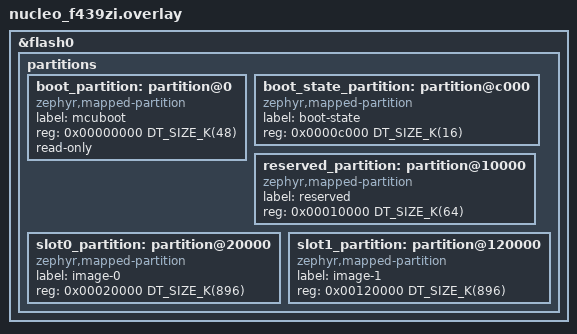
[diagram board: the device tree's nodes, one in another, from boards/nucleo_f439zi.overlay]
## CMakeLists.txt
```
# SPDX-License-Identifier: Apache-2.0
cmake_minimum_required(VERSION 3.28.0)

find_package(Zephyr REQUIRED HINTS $ENV{ZEPHYR_BASE})
project(sber_ota LANGUAGES C)

target_sources(app PRIVATE src/main.c src/rww_test.c)
```

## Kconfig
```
# Kconfig приложения: Zephyr подхватывает файл Kconfig в корне приложения
# автоматически; в конце обязательно source "Kconfig.zephyr".

mainmenu "sber-ota"

menu "sber-ota"

config SBER_OTA_AUTO_CONFIRM
	bool "Confirm running image after first answered network request"
	default y
	depends on MCUBOOT_IMG_MANAGER
	help
	  После обновления MCUboot запускает новый образ в состоянии "testing":
	  если до следующего сброса его не подтвердить, загрузчик откатит
	  предыдущий. Приложение подтверждает себя (boot_write_img_confirmed)
	  только после того, как приняло и ответило на первый UDP-запрос по сети:
	  это доказывает, что стек, драйвер Ethernet и обработчик живы.
	  Выключить, чтобы собрать "плохой" образ для демонстрации отката.

endmenu

source "Kconfig.zephyr"
```

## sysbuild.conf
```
# sysbuild: собрать MCUboot + приложение одной командой
#   west build -b nucleo_f439zi --sysbuild app/sber-ota -d build_sber_sb
SB_CONFIG_BOOTLOADER_MCUBOOT=y

# swap-move: не нужен scratch, образ в slot0 после обновления остаётся на своём
# адресе (приложение линкуется один раз). Запасной режим перед direct-XIP.
# Слоты 7+7 секторов по 128 КБ: swap-move требует num_pri == num_sec или
# num_pri == num_sec+1; при равенстве последний сектор primary уходит под
# сдвиг + trailer, полезный объём образа = 6 * 128 КБ - trailer.
SB_CONFIG_MCUBOOT_MODE_SWAP_USING_MOVE=y

# ECDSA P-256: подпись 64 байта, верификация быстрее RSA-2048 и меньше кода
# в загрузчике. Ключ по умолчанию — ТЕСТОВЫЙ root-ec-p256.pem из репозитория
# MCUboot (публично известен!). Боевой ключ задавать через
# SB_CONFIG_BOOT_SIGNATURE_KEY_FILE вне репозитория.
SB_CONFIG_BOOT_SIGNATURE_TYPE_ECDSA_P256=y
```

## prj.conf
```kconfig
# --- Сеть: только IPv4, UDP + TCP, BSD-сокеты ---
CONFIG_NETWORKING=y
CONFIG_NET_IPV4=y
CONFIG_NET_IPV6=n
CONFIG_NET_UDP=y
CONFIG_NET_TCP=y
CONFIG_NET_SOCKETS=y
CONFIG_POSIX_API=y
CONFIG_NET_CONNECTION_MANAGER=y

# Статический адрес платы (DHCP — шаг 4)
CONFIG_NET_CONFIG_SETTINGS=y
CONFIG_NET_CONFIG_NEED_IPV4=y
CONFIG_NET_CONFIG_MY_IPV4_ADDR="192.168.7.1"
CONFIG_NET_CONFIG_MY_IPV4_NETMASK="255.255.255.0"

# Буферы: эхо-сервер + будущая загрузка образа кусками 1–2 КБ
CONFIG_NET_PKT_RX_COUNT=16
CONFIG_NET_PKT_TX_COUNT=16
CONFIG_NET_BUF_RX_COUNT=64
CONFIG_NET_BUF_TX_COUNT=64
CONFIG_NET_MAX_CONTEXTS=10

# --- Ядро ---
CONFIG_MAIN_STACK_SIZE=4096
CONFIG_ENTROPY_GENERATOR=y
CONFIG_INIT_STACKS=y
CONFIG_REBOOT=y   # kernel reboot в shell; нужен и mcumgr os reset

# --- Flash: нужна для шага 2 (запись во второй банк) и проверки partitions ---
CONFIG_FLASH=y
CONFIG_FLASH_MAP=y
CONFIG_FLASH_PAGE_LAYOUT=y

# --- GPIO (LED «жив») ---
CONFIG_GPIO=y

# --- Логирование и shell (консоль ST-Link, 115200) ---
CONFIG_LOG=y
CONFIG_LOG_MODE_DEFERRED=y
CONFIG_PRINTK=y
CONFIG_NET_LOG=y
CONFIG_NET_STATISTICS=y
CONFIG_SHELL=y
CONFIG_NET_SHELL=y
CONFIG_FLASH_SHELL=y

# --- mcumgr / SMP по UDP (порт 1337): обновление и управление по сети ---
# Транспорт сам открывает сокет по NET_EVENT_L4_CONNECTED (UDP_AUTOMATIC_INIT).
CONFIG_MCUMGR=y
CONFIG_ZCBOR=y
CONFIG_CRC=y
CONFIG_NET_BUF=y
CONFIG_MCUMGR_TRANSPORT_UDP=y
CONFIG_MCUMGR_TRANSPORT_UDP_IPV4=y
CONFIG_MCUMGR_TRANSPORT_UDP_IPV6=n
# img_mgmt: приём образа в slot1 через stream_flash.
# ERASE_PROGRESSIVELY: стирать сектор по мере заполнения (1,9 с на 128 КБ),
# а не весь слот при первом куске (13,5 с > таймаут клиента).
CONFIG_IMG_MANAGER=y
CONFIG_STREAM_FLASH=y
CONFIG_IMG_ERASE_PROGRESSIVELY=y
CONFIG_MCUMGR_GRP_IMG=y
# os_mgmt: echo, reset, сведения о загрузчике
CONFIG_MCUMGR_GRP_OS=y
CONFIG_MCUMGR_GRP_OS_BOOTLOADER_INFO=y
# mcumgr params: клиент узнаёт размер буфера SMP и подбирает размер куска
CONFIG_MCUMGR_GRP_OS_MCUMGR_PARAMS=y
# Обработчики SMP работают в system workqueue — ему нужен стек побольше
CONFIG_SYSTEM_WORKQUEUE_STACK_SIZE=2304
```

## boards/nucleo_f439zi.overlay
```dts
/*
 * Раскладка flash STM32F439ZI (2 МБ, dual-bank) под MCUboot direct-XIP.
 *
 * Почему свой overlay: дефолтный nucleo_f439zi.dts даёт 32 КБ под bootloader
 * (не кратно секторной структуре 16/16/16/16/64 КБ) и несимметричные слоты
 * (896 КБ vs 768 КБ). Для direct-XIP слоты должны быть одинаковыми и лежать
 * на одинаковых смещениях внутри банков, чтобы совпадала структура секторов.
 *
 * Bank 1:  сектора 0-2   (3 x 16 КБ)  bootloader
 *          сектор  3     (16 КБ)      boot state / конфиг
 *          сектор  4     (64 КБ)      резерв
 *          сектора 5-11  (896 КБ)     slot0 (A) @ 0x08020000
 * Bank 2:  сектора 12-16              зеркало 0-4, не используются
 *          сектора 17-23 (896 КБ)     slot1 (B) @ 0x08120000
 */

/delete-node/ &boot_partition;
/delete-node/ &slot0_partition;
/delete-node/ &slot1_partition;

&flash0 {
	partitions {
		#address-cells = <1>;
		#size-cells = <1>;
		ranges;

		boot_partition: partition@0 {
			compatible = "zephyr,mapped-partition";
			label = "mcuboot";
			reg = <0x00000000 DT_SIZE_K(48)>;
			read-only;
		};

		boot_state_partition: partition@c000 {
			compatible = "zephyr,mapped-partition";
			label = "boot-state";
			reg = <0x0000c000 DT_SIZE_K(16)>;
		};

		reserved_partition: partition@10000 {
			compatible = "zephyr,mapped-partition";
			label = "reserved";
			reg = <0x00010000 DT_SIZE_K(64)>;
		};

		slot0_partition: partition@20000 {
			compatible = "zephyr,mapped-partition";
			label = "image-0";
			reg = <0x00020000 DT_SIZE_K(896)>;
		};

		slot1_partition: partition@120000 {
			compatible = "zephyr,mapped-partition";
			label = "image-1";
			reg = <0x00120000 DT_SIZE_K(896)>;
		};
	};
};
```

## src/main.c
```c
/*
 * sber-ota: UDP/TCP echo-сервер на NUCLEO-F439ZI (Zephyr).
 * Шаг 1: каркас приложения с сетью и логированием.
 * Шаг 2 (следующий): запись во второй банк flash при живой сети.
 *
 * SPDX-License-Identifier: Apache-2.0
 */

#include <zephyr/kernel.h>
#include <zephyr/logging/log.h>
#include <zephyr/drivers/gpio.h>
#include <zephyr/net/socket.h>
#include <zephyr/net/net_if.h>
#include <zephyr/net/net_mgmt.h>
#include <zephyr/net/net_event.h>
#include <zephyr/net/conn_mgr_monitor.h>
#include <zephyr/storage/flash_map.h>
#include <zephyr/dfu/mcuboot.h>
#include <errno.h>
#include <zephyr/app_version.h>
#include <cmsis_core.h>

/* Строки лога — ASCII: консоли/CI/парсеры не всегда понимают UTF-8 */
LOG_MODULE_REGISTER(sber_ota, LOG_LEVEL_INF);

#define ECHO_PORT      4242
#define RX_BUF_SIZE    1500
#define THREAD_STACK   2048
#define THREAD_PRIO    K_PRIO_PREEMPT(8)

static const struct gpio_dt_spec led = GPIO_DT_SPEC_GET(DT_ALIAS(led0), gpios);

/* Серверы стартуют после события L4_CONNECTED от connection manager */
static K_SEM_DEFINE(net_ready, 0, 1);

static void l4_event_handler(uint64_t event, struct net_if *iface, void *info,
			     size_t info_length, void *user_data)
{
	ARG_UNUSED(iface);
	ARG_UNUSED(info);
	ARG_UNUSED(info_length);
	ARG_UNUSED(user_data);

	if (event == NET_EVENT_L4_CONNECTED) {
		LOG_INF("network up");
		k_sem_give(&net_ready);
	} else if (event == NET_EVENT_L4_DISCONNECTED) {
		LOG_WRN("network down");
	}
}

NET_MGMT_REGISTER_EVENT_HANDLER(l4_handler,
				NET_EVENT_L4_CONNECTED | NET_EVENT_L4_DISCONNECTED,
				l4_event_handler, NULL);

/*
 * Подтверждение образа после обновления. MCUboot запускает новый образ как
 * "testing"; без подтверждения следующий сброс откатит предыдущий. Критерий
 * "образ исправен" здесь — принят и отвечен первый UDP-запрос: значит, стек,
 * драйвер Ethernet и приложение живы и доступны для скрипта обновления.
 */
static void confirm_image_after_first_reply(void)
{
	static bool done;
	int rc;

	if (done) {
		return;
	}
	done = true;

	if (!IS_ENABLED(CONFIG_SBER_OTA_AUTO_CONFIRM)) {
		LOG_WRN("auto-confirm disabled: image stays in testing state");
		return;
	}
	if (boot_is_img_confirmed()) {
		return;
	}
	rc = boot_write_img_confirmed();
	if (rc) {
		LOG_ERR("boot_write_img_confirmed: %d", rc);
	} else {
		LOG_INF("image confirmed after first network reply");
	}
}

static void wait_net_ready(void)
{
	k_sem_take(&net_ready, K_FOREVER);
	k_sem_give(&net_ready); /* передать эстафету второму потоку */
}

/* ---------- UDP echo ---------- */
static void udp_echo_thread(void *a, void *b, void *c)
{
	static uint8_t buf[RX_BUF_SIZE];
	struct sockaddr_in addr = {
		.sin_family = AF_INET,
		.sin_port = htons(ECHO_PORT),
		.sin_addr.s_addr = htonl(INADDR_ANY),
	};
	int sock;

	wait_net_ready();

	sock = zsock_socket(AF_INET, SOCK_DGRAM, IPPROTO_UDP);
	if (sock < 0) {
		LOG_ERR("UDP socket: %d", errno);
		return;
	}
	if (zsock_bind(sock, (struct sockaddr *)&addr, sizeof(addr)) < 0) {
		LOG_ERR("UDP bind: %d", errno);
		zsock_close(sock);
		return;
	}
	LOG_INF("UDP echo listening on port %d", ECHO_PORT);

	while (1) {
		struct sockaddr_in peer;
		socklen_t peer_len = sizeof(peer);
		ssize_t n = zsock_recvfrom(sock, buf, sizeof(buf), 0,
					   (struct sockaddr *)&peer, &peer_len);

		if (n < 0) {
			LOG_ERR("UDP recvfrom: %d", errno);
			continue;
		}
		if (zsock_sendto(sock, buf, n, 0, (struct sockaddr *)&peer, peer_len) < 0) {
			LOG_ERR("UDP sendto: %d", errno);
			continue;
		}
		confirm_image_after_first_reply();
	}
}

/* ---------- TCP echo (один клиент за раз) ---------- */
static void tcp_echo_thread(void *a, void *b, void *c)
{
	static uint8_t buf[RX_BUF_SIZE];
	struct sockaddr_in addr = {
		.sin_family = AF_INET,
		.sin_port = htons(ECHO_PORT),
		.sin_addr.s_addr = htonl(INADDR_ANY),
	};
	int sock;

	wait_net_ready();

	sock = zsock_socket(AF_INET, SOCK_STREAM, IPPROTO_TCP);
	if (sock < 0) {
		LOG_ERR("TCP socket: %d", errno);
		return;
	}
	if (zsock_bind(sock, (struct sockaddr *)&addr, sizeof(addr)) < 0 ||
	    zsock_listen(sock, 2) < 0) {
		LOG_ERR("TCP bind/listen: %d", errno);
		zsock_close(sock);
		return;
	}
	LOG_INF("TCP echo listening on port %d", ECHO_PORT);

	while (1) {
		struct sockaddr_in peer;
		socklen_t peer_len = sizeof(peer);
		char ip[NET_IPV4_ADDR_LEN];
		int client = zsock_accept(sock, (struct sockaddr *)&peer, &peer_len);

		if (client < 0) {
			LOG_ERR("TCP accept: %d", errno);
			continue;
		}
		zsock_inet_ntop(AF_INET, &peer.sin_addr, ip, sizeof(ip));
		LOG_INF("TCP client %s:%u", ip, ntohs(peer.sin_port));

		while (1) {
			ssize_t n = zsock_recv(client, buf, sizeof(buf), 0);
			ssize_t off = 0;

			if (n <= 0) {
				break;
			}
			while (off < n) {
				ssize_t s = zsock_send(client, buf + off, n - off, 0);

				if (s < 0) {
					n = -1;
					break;
				}
				off += s;
			}
			if (n < 0) {
				break;
			}
		}
		LOG_INF("TCP client disconnected");
		zsock_close(client);
	}
}

K_THREAD_DEFINE(udp_tid, THREAD_STACK, udp_echo_thread, NULL, NULL, NULL, THREAD_PRIO, 0, 0);
K_THREAD_DEFINE(tcp_tid, THREAD_STACK, tcp_echo_thread, NULL, NULL, NULL, THREAD_PRIO, 0, 0);

/* Распечатать partitions из DTS: проверка, что overlay подхватился */
static void log_flash_layout(void)
{
	const struct flash_area *fa;
	const uint8_t ids[] = {
		PARTITION_ID(boot_partition),
		PARTITION_ID(boot_state_partition),
		PARTITION_ID(reserved_partition),
		PARTITION_ID(slot0_partition),
		PARTITION_ID(slot1_partition),
	};

	for (size_t i = 0; i < ARRAY_SIZE(ids); i++) {
		if (flash_area_open(ids[i], &fa) == 0) {
			LOG_INF("partition %u: off 0x%08lx size %4u KB dev %s", fa->fa_id,
				(unsigned long)fa->fa_off, (unsigned int)(fa->fa_size / 1024),
				fa->fa_dev->name);
			flash_area_close(fa);
		}
	}
}

int main(void)
{
	/* VTOR показывает, откуда реально исполняемся: 0x08000000 без загрузчика,
	 * 0x08020000 (+0x200 заголовка MCUboot) — если нас запустил MCUboot из slot0 */
	LOG_INF("sber-ota %s start, board=%s, VTOR=0x%08x", APP_VERSION_EXTENDED_STRING,
		CONFIG_BOARD, (unsigned int)SCB->VTOR);

	if (gpio_is_ready_dt(&led)) {
		gpio_pin_configure_dt(&led, GPIO_OUTPUT_INACTIVE);
	}

	LOG_INF("image state: %s", boot_is_img_confirmed() ? "confirmed"
		: "testing (reverts on next reset unless confirmed)");
	log_flash_layout();

	/* conn_mgr: если интерфейс уже поднят, разослать текущее состояние */
	conn_mgr_mon_resend_status();

	while (1) {
		gpio_pin_toggle_dt(&led);
		k_sleep(K_MSEC(500));
	}
	return 0;
}
```

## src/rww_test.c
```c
/*
 * Проверка read-while-write: стирание/запись slot1 (банк 2) из shell,
 * пока в банке 1 исполняется код и крутятся сетевые потоки.
 *
 * Зачем: на F4 dual-bank означает, что CPU не останавливается на выборке
 * команд из банка 1, пока контроллер стирает сектор банка 2. Если бы это
 * было не так, каждое стирание 128 КБ сектора (~1-2 с) замораживало бы
 * сеть. Это также проверяет, что partitions из DTS совпадают с реальными
 * секторами (стирание ложится ровно на границы страниц).
 *
 * Команды: rww info | rww erase [pages] | rww write [kb] | rww verify [kb]
 * Все печатают строку "#RWW <cmd> done <ms>" — маркер для хост-скрипта.
 *
 * SPDX-License-Identifier: Apache-2.0
 */

#include <zephyr/kernel.h>
#include <zephyr/shell/shell.h>
#include <zephyr/storage/flash_map.h>
#include <zephyr/drivers/flash.h>
#include <zephyr/logging/log.h>
#include <stdlib.h>
#include <string.h>

LOG_MODULE_REGISTER(rww, LOG_LEVEL_INF);

#define TARGET_ID    PARTITION_ID(slot1_partition)
#define CHUNK        1024U

/* Детерминированный шаблон: слово зависит от абсолютного смещения в разделе */
static inline uint32_t pattern(uint32_t off)
{
	return (off * 2654435761U) ^ 0xA5A5A5A5U;
}

static void fill_pattern(uint8_t *buf, uint32_t off, size_t len)
{
	for (size_t i = 0; i < len; i += 4) {
		uint32_t w = pattern(off + i);

		memcpy(buf + i, &w, 4);
	}
}

static int open_target(const struct shell *sh, const struct flash_area **fa)
{
	int rc = flash_area_open(TARGET_ID, fa);

	if (rc) {
		shell_error(sh, "flash_area_open: %d", rc);
	}
	return rc;
}

static int cmd_info(const struct shell *sh, size_t argc, char **argv)
{
	const struct flash_area *fa;
	struct flash_pages_info pi;
	uint32_t off = 0;

	if (open_target(sh, &fa)) {
		return -EIO;
	}
	shell_print(sh, "slot1: dev=%s off=0x%08lx size=%u KB", fa->fa_dev->name,
		    (unsigned long)fa->fa_off, (unsigned int)(fa->fa_size / 1024));
	while (off < fa->fa_size) {
		if (flash_get_page_info_by_offs(fa->fa_dev, fa->fa_off + off, &pi)) {
			break;
		}
		shell_print(sh, "  sector %2u: 0x%08lx + %3u KB", pi.index,
			    (unsigned long)pi.start_offset, (unsigned int)(pi.size / 1024));
		off += pi.size;
	}
	flash_area_close(fa);
	return 0;
}

static int cmd_erase(const struct shell *sh, size_t argc, char **argv)
{
	const struct flash_area *fa;
	struct flash_pages_info pi;
	uint32_t off = 0, n = 0;
	uint32_t limit = (argc > 1) ? strtoul(argv[1], NULL, 0) : UINT32_MAX;
	int64_t t0 = k_uptime_get();

	if (open_target(sh, &fa)) {
		return -EIO;
	}
	while (off < fa->fa_size && n < limit) {
		int64_t ts = k_uptime_get();
		int rc;

		if (flash_get_page_info_by_offs(fa->fa_dev, fa->fa_off + off, &pi)) {
			break;
		}
		rc = flash_area_erase(fa, off, pi.size);
		shell_print(sh, "#RWW erase sector %u (%u KB) rc=%d %lld ms", pi.index,
			    (unsigned int)(pi.size / 1024), rc, k_uptime_get() - ts);
		if (rc) {
			break;
		}
		off += pi.size;
		n++;
	}
	flash_area_close(fa);
	shell_print(sh, "#RWW erase done %lld", k_uptime_get() - t0);
	return 0;
}

static int cmd_write(const struct shell *sh, size_t argc, char **argv)
{
	static uint8_t buf[CHUNK];
	const struct flash_area *fa;
	uint32_t len, off;
	int64_t t0 = k_uptime_get();
	int rc = 0;

	if (open_target(sh, &fa)) {
		return -EIO;
	}
	len = (argc > 1) ? strtoul(argv[1], NULL, 0) * 1024 : fa->fa_size;
	len = MIN(len, fa->fa_size);

	for (off = 0; off < len; off += CHUNK) {
		fill_pattern(buf, off, CHUNK);
		rc = flash_area_write(fa, off, buf, CHUNK);
		if (rc) {
			shell_error(sh, "write @0x%x rc=%d", off, rc);
			break;
		}
	}
	flash_area_close(fa);

	int64_t dt = k_uptime_get() - t0;

	shell_print(sh, "#RWW write done %lld ms, %u KB, %lld KB/s rc=%d", dt, off / 1024,
		    dt ? (off / 1024) * 1000 / dt : 0, rc);
	return rc;
}

static int cmd_verify(const struct shell *sh, size_t argc, char **argv)
{
	static uint8_t buf[CHUNK], ref[CHUNK];
	const struct flash_area *fa;
	uint32_t len, off, bad = 0;
	int64_t t0 = k_uptime_get();

	if (open_target(sh, &fa)) {
		return -EIO;
	}
	len = (argc > 1) ? strtoul(argv[1], NULL, 0) * 1024 : fa->fa_size;
	len = MIN(len, fa->fa_size);

	for (off = 0; off < len; off += CHUNK) {
		int rc = flash_area_read(fa, off, buf, CHUNK);

		if (rc) {
			shell_error(sh, "read @0x%x rc=%d", off, rc);
			break;
		}
		fill_pattern(ref, off, CHUNK);
		if (memcmp(buf, ref, CHUNK)) {
			if (bad < 5) {
				shell_warn(sh, "mismatch @0x%x", off);
			}
			bad++;
		}
	}
	flash_area_close(fa);
	shell_print(sh, "#RWW verify done %lld ms, %u KB, bad chunks %u", k_uptime_get() - t0,
		    off / 1024, bad);
	return bad ? -EIO : 0;
}

SHELL_STATIC_SUBCMD_SET_CREATE(rww_cmds,
	SHELL_CMD(info, NULL, "slot1 sectors", cmd_info),
	SHELL_CMD(erase, NULL, "erase slot1 [pages]", cmd_erase),
	SHELL_CMD(write, NULL, "write pattern [kb]", cmd_write),
	SHELL_CMD(verify, NULL, "verify pattern [kb]", cmd_verify),
	SHELL_SUBCMD_SET_END);
SHELL_CMD_REGISTER(rww, &rww_cmds, "read-while-write test on slot1", NULL);
```
